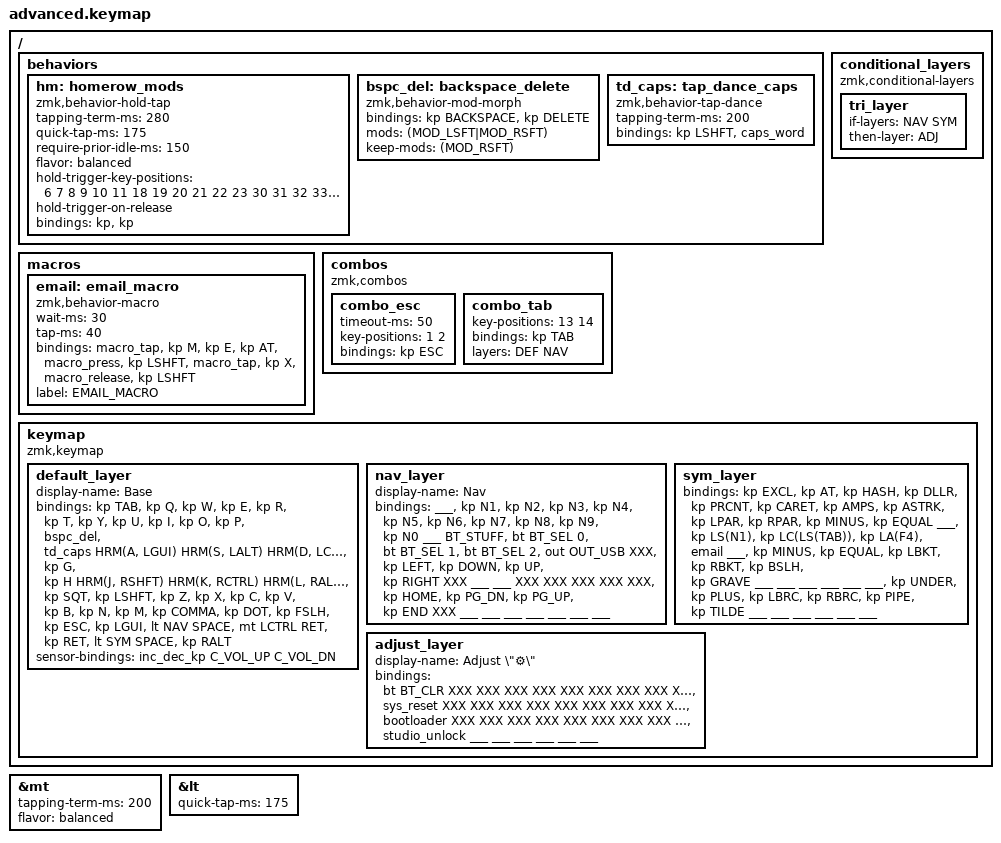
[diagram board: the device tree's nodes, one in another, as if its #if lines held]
/*
 * Advanced fixture: combos, macros, hold-taps, mod-morphs, conditional layers,
 * preprocessor macros and comments in awkward places. Ünïcödé in comments → ✓
 */

#include <behaviors.dtsi>
#include <dt-bindings/zmk/keys.h>
#include <dt-bindings/zmk/bt.h>
#include <dt-bindings/zmk/outputs.h>

#define DEF 0
#define NAV 1   // navigation
#define SYM 2   /* symbols */
#define ADJ 3

#define XXX &none
#define ___ &trans
#define HRM(tap, mod) &hm mod tap

#ifdef CONFIG_WIRELESS
#define BT_STUFF &bt BT_CLR
#else
#define BT_STUFF &none
#endif

&mt {
    tapping-term-ms = <200>;
    flavor = "balanced";
};

&lt { quick-tap-ms = <175>; };

/ {
    behaviors {
        hm: homerow_mods {
            compatible = "zmk,behavior-hold-tap";
            #binding-cells = <2>;
            tapping-term-ms = <280>;
            quick-tap-ms = <175>;
            require-prior-idle-ms = <150>;
            flavor = "balanced";
            hold-trigger-key-positions = <6 7 8 9 10 11 18 19 20 21 22 23 30 31 32 33 34 35 39 40 41>;
            hold-trigger-on-release;
            bindings = <&kp>, <&kp>;
        };

        bspc_del: backspace_delete {
            compatible = "zmk,behavior-mod-morph";
            #binding-cells = <0>;
            bindings = <&kp BACKSPACE>, <&kp DELETE>;
            mods = <(MOD_LSFT|MOD_RSFT)>;
            keep-mods = <(MOD_RSFT)>;
        };

        td_caps: tap_dance_caps {
            compatible = "zmk,behavior-tap-dance";
            #binding-cells = <0>;
            tapping-term-ms = <200>;
            bindings = <&kp LSHFT>, <&caps_word>;
        };
    };

    macros {
        email: email_macro {
            compatible = "zmk,behavior-macro";
            #binding-cells = <0>;
            wait-ms = <30>;
            tap-ms = <40>;
            bindings
                = <&macro_tap &kp M &kp E &kp AT>
                , <&macro_press &kp LSHFT>
                , <&macro_tap &kp X>
                , <&macro_release &kp LSHFT>
                ;
            label = "EMAIL_MACRO";
        };
    };

    combos {
        compatible = "zmk,combos";
        combo_esc {
            timeout-ms = <50>;
            key-positions = <1 2>;
            bindings = <&kp ESC>;
        };
        combo_tab {
            key-positions = <13 14>;
            bindings = <&kp TAB>;
            layers = <DEF NAV>;
        };
    };

    conditional_layers {
        compatible = "zmk,conditional-layers";
        tri_layer {
            if-layers = <NAV SYM>;
            then-layer = <ADJ>;
        };
    };

    keymap {
        compatible = "zmk,keymap";

        default_layer {
            display-name = "Base";
            bindings = <
    &kp TAB  &kp Q        &kp W        &kp E        &kp R        &kp T              &kp Y  &kp U        &kp I        &kp O        &kp P           &bspc_del
    &td_caps HRM(A, LGUI) HRM(S, LALT) HRM(D, LCTRL) HRM(F, LSHFT) &kp G             &kp H  HRM(J, RSHFT) HRM(K, RCTRL) HRM(L, RALT) HRM(SEMI, RGUI) &kp SQT
    &kp LSHFT &kp Z       &kp X        &kp C        &kp V        &kp B              &kp N  &kp M        &kp COMMA    &kp DOT      &kp FSLH        &kp ESC
                                       &kp LGUI     &lt NAV SPACE &mt LCTRL RET     &kp RET &lt SYM SPACE &kp RALT
            >;
            sensor-bindings = <&inc_dec_kp C_VOL_UP C_VOL_DN>;
        };

        nav_layer {
            display-name = "Nav";
            // A comment inside the bindings block's node.
            bindings = <
    ___ &kp N1 &kp N2 &kp N3 &kp N4 &kp N5          &kp N6 &kp N7 &kp N8 &kp N9 &kp N0 ___
    BT_STUFF &bt BT_SEL 0 &bt BT_SEL 1 &bt BT_SEL 2 &out OUT_USB XXX    &kp LEFT &kp DOWN &kp UP &kp RIGHT XXX ___
    ___ XXX XXX XXX XXX XXX                         &kp HOME &kp PG_DN &kp PG_UP &kp END XXX ___
                  ___ ___ ___                       ___ ___ ___
            >;
        };

        sym_layer {
            bindings = <
    &kp EXCL &kp AT &kp HASH &kp DLLR &kp PRCNT &kp CARET   &kp AMPS &kp ASTRK &kp LPAR &kp RPAR &kp MINUS &kp EQUAL
    ___ &kp LS(N1) &kp LC(LS(TAB)) &kp LA(F4) /* inline */ &email ___   &kp MINUS &kp EQUAL &kp LBKT &kp RBKT &kp BSLH &kp GRAVE
    ___ ___ ___ ___ ___ ___                         &kp UNDER &kp PLUS &kp LBRC &kp RBRC &kp PIPE &kp TILDE
                  ___ ___ ___                       ___ ___ ___
            >;
        };

        adjust_layer {
            display-name = "Adjust \"⚙\"";
            bindings = <
    &bt BT_CLR XXX XXX XXX XXX XXX                  XXX XXX XXX XXX XXX &sys_reset
    XXX XXX XXX XXX XXX XXX                         XXX XXX XXX XXX XXX &bootloader
    XXX XXX XXX XXX XXX XXX                         XXX XXX XXX XXX XXX &studio_unlock
                  ___ ___ ___                       ___ ___ ___
            >;
        };
    };
};
